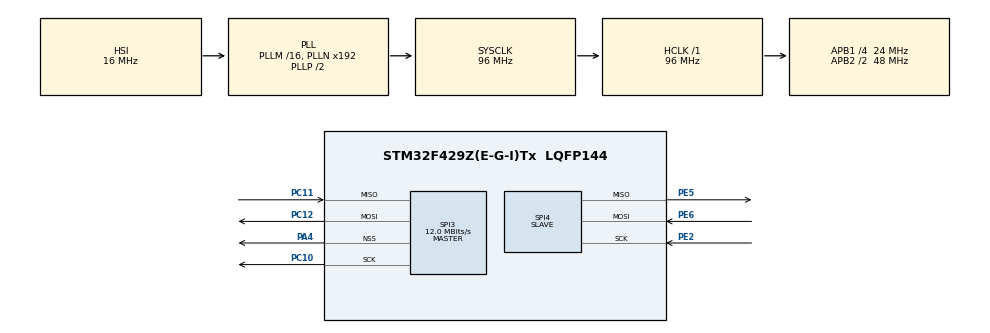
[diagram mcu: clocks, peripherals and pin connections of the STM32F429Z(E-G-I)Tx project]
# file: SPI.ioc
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Mcu.Family=STM32F4
Mcu.Name=STM32F429Z(E-G-I)Tx
Mcu.Package=LQFP144
NVIC.PriorityGroup=NVIC_PRIORITYGROUP_4
NVIC.SPI3_IRQn=true\:0\:0\:false\:false\:true
PA13.Mode=Serial_Wire
PA13.Signal=SYS_JTMS-SWDIO
PA14.Mode=Serial_Wire
PA14.Signal=SYS_JTCK-SWCLK
PA4.Mode=NSS_Signal_Hard_Output
PA4.Signal=SPI3_NSS
PC10.Mode=Full_Duplex_Master
PC10.Signal=SPI3_SCK
PC11.Mode=Full_Duplex_Master
PC11.Signal=SPI3_MISO
PC12.Mode=Full_Duplex_Master
PC12.Signal=SPI3_MOSI
PE2.Mode=Full_Duplex_Slave
PE2.Signal=SPI4_SCK
PE5.Mode=Full_Duplex_Slave
PE5.Signal=SPI4_MISO
PE6.Mode=Full_Duplex_Slave
PE6.Signal=SPI4_MOSI
PH0/OSC_IN.Mode=HSE-External-Oscillator
PH0/OSC_IN.Signal=RCC_OSC_IN
PH1/OSC_OUT.Mode=HSE-External-Oscillator
PH1/OSC_OUT.Signal=RCC_OSC_OUT
ProjectManager.HeapSize=0x200
ProjectManager.StackSize=0x400
ProjectManager.TargetToolchain=SW4STM32
RCC.AHBFreq_Value=96000000
RCC.APB1CLKDivider=RCC_HCLK_DIV4
RCC.APB1Freq_Value=24000000
RCC.APB1TimFreq_Value=48000000
RCC.APB2CLKDivider=RCC_HCLK_DIV2
RCC.APB2Freq_Value=48000000
RCC.APB2TimFreq_Value=96000000
RCC.CortexFreq_Value=96000000
RCC.HCLKFreq_Value=96000000
RCC.HSE_VALUE=8000000
RCC.HSI_VALUE=16000000
RCC.LSE_VALUE=32768
RCC.SYSCLKFreq_VALUE=96000000
RCC.SYSCLKSource=RCC_SYSCLKSOURCE_PLLCLK
RCC.VCOOutputFreq_Value=192000000
SPI3.BaudRatePrescaler=SPI_BAUDRATEPRESCALER_2
SPI3.CalculateBaudRate=12.0 MBits/s
SPI3.Direction=SPI_DIRECTION_2LINES
SPI3.Mode=SPI_MODE_MASTER
SPI3.VirtualNSS=VM_NSSHARD
SPI3.VirtualType=VM_MASTER
SPI4.Direction=SPI_DIRECTION_2LINES
SPI4.Mode=SPI_MODE_SLAVE
SPI4.VirtualType=VM_SLAVE
board=SPI

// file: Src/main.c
/**
  ******************************************************************************
  * File Name          : main.c
  * Description        : Main program body
  ******************************************************************************
  ** This notice applies to any and all portions of this file
  * that are not between comment pairs USER CODE BEGIN and
  * USER CODE END. Other portions of this file, whether
  * inserted by the user or by software development tools
  * are owned by their respective copyright owners.
  *
  * COPYRIGHT(c) 2017 STMicroelectronics
  *
  * Redistribution and use in source and binary forms, with or without modification,
  * are permitted provided that the following conditions are met:
  *   1. Redistributions of source code must retain the above copyright notice,
  *      this list of conditions and the following disclaimer.
  *   2. Redistributions in binary form must reproduce the above copyright notice,
  *      this list of conditions and the following disclaimer in the documentation
  *      and/or other materials provided with the distribution.
  *   3. Neither the name of STMicroelectronics nor the names of its contributors
  *      may be used to endorse or promote products derived from this software
  *      without specific prior written permission.
  *
  * THIS SOFTWARE IS PROVIDED BY THE COPYRIGHT HOLDERS AND CONTRIBUTORS "AS IS"
  * AND ANY EXPRESS OR IMPLIED WARRANTIES, INCLUDING, BUT NOT LIMITED TO, THE
  * IMPLIED WARRANTIES OF MERCHANTABILITY AND FITNESS FOR A PARTICULAR PURPOSE ARE
  * DISCLAIMED. IN NO EVENT SHALL THE COPYRIGHT HOLDER OR CONTRIBUTORS BE LIABLE
  * FOR ANY DIRECT, INDIRECT, INCIDENTAL, SPECIAL, EXEMPLARY, OR CONSEQUENTIAL
  * DAMAGES (INCLUDING, BUT NOT LIMITED TO, PROCUREMENT OF SUBSTITUTE GOODS OR
  * SERVICES; LOSS OF USE, DATA, OR PROFITS; OR BUSINESS INTERRUPTION) HOWEVER
  * CAUSED AND ON ANY THEORY OF LIABILITY, WHETHER IN CONTRACT, STRICT LIABILITY,
  * OR TORT (INCLUDING NEGLIGENCE OR OTHERWISE) ARISING IN ANY WAY OUT OF THE USE
  * OF THIS SOFTWARE, EVEN IF ADVISED OF THE POSSIBILITY OF SUCH DAMAGE.
  *
  ******************************************************************************
  */
#include "main.h"
#include "stm32f4xx_hal.h"

SPI_HandleTypeDef hspi3;
SPI_HandleTypeDef hspi4;

/* USER CODE BEGIN PV */
/* Private variables ---------------------------------------------------------*/

/* USER CODE END PV */

void SystemClock_Config(void);
static void MX_GPIO_Init(void);
static void MX_SPI3_Init(void);
static void MX_SPI4_Init(void);

/* USER CODE BEGIN PFP */
/* Private function prototypes -----------------------------------------------*/

/* USER CODE END PFP */

int main(void)
{

  /* USER CODE BEGIN 1 */
	char txBuffer[]={0x10,0x11,0x12,0x13};
	char rxBuffer[8];
  /* USER CODE END 1 */

  /* MCU Configuration----------------------------------------------------------*/

  /* Reset of all peripherals, Initializes the Flash interface and the Systick. */
  HAL_Init();

  /* Configure the system clock */
  SystemClock_Config();

  /* Initialize all configured peripherals */
  MX_GPIO_Init();
  MX_SPI3_Init();
  MX_SPI4_Init();

  /* Infinite loop */
  /* USER CODE BEGIN WHILE */
  while (1)
  {
	  int i;
	  volatile HAL_StatusTypeDef result;
	 	  result = HAL_SPI_TransmitReceive_IT(&hspi3,txBuffer, rxBuffer, 4);
	 	  	  if(result == HAL_ERROR){
	  	  		  while(1);
	 	  	  }
	 	 	  result = HAL_SPI_GetState(&hspi3);

	 	 	  HAL_Delay(1000);
	 	 	  for(i=0; i<4; i++){
	 	  		  rxBuffer[i] = 0;
	 	  		  txBuffer[i] += 4;
  /* USER CODE END WHILE */

  /* USER CODE BEGIN 3 */

  }
  /* USER CODE BEGIN 3 */

  }
  /* USER CODE END 3 */

}

/** System Clock Configuration
*/
void SystemClock_Config(void)
{

  RCC_OscInitTypeDef RCC_OscInitStruct;
  RCC_ClkInitTypeDef RCC_ClkInitStruct;

    /**Configure the main internal regulator output voltage
    */
  __HAL_RCC_PWR_CLK_ENABLE();

  __HAL_PWR_VOLTAGESCALING_CONFIG(PWR_REGULATOR_VOLTAGE_SCALE3);

    /**Initializes the CPU, AHB and APB busses clocks
    */
  RCC_OscInitStruct.OscillatorType = RCC_OSCILLATORTYPE_HSI;
  RCC_OscInitStruct.HSIState = RCC_HSI_ON;
  RCC_OscInitStruct.HSICalibrationValue = 16;
  RCC_OscInitStruct.PLL.PLLState = RCC_PLL_ON;
  RCC_OscInitStruct.PLL.PLLSource = RCC_PLLSOURCE_HSI;
  RCC_OscInitStruct.PLL.PLLM = 16;
  RCC_OscInitStruct.PLL.PLLN = 192;
  RCC_OscInitStruct.PLL.PLLP = RCC_PLLP_DIV2;
  RCC_OscInitStruct.PLL.PLLQ = 4;
  if (HAL_RCC_OscConfig(&RCC_OscInitStruct) != HAL_OK)
  {
    _Error_Handler(__FILE__, __LINE__);
  }

    /**Initializes the CPU, AHB and APB busses clocks
    */
  RCC_ClkInitStruct.ClockType = RCC_CLOCKTYPE_HCLK|RCC_CLOCKTYPE_SYSCLK
                              |RCC_CLOCKTYPE_PCLK1|RCC_CLOCKTYPE_PCLK2;
  RCC_ClkInitStruct.SYSCLKSource = RCC_SYSCLKSOURCE_PLLCLK;
  RCC_ClkInitStruct.AHBCLKDivider = RCC_SYSCLK_DIV1;
  RCC_ClkInitStruct.APB1CLKDivider = RCC_HCLK_DIV4;
  RCC_ClkInitStruct.APB2CLKDivider = RCC_HCLK_DIV2;

  if (HAL_RCC_ClockConfig(&RCC_ClkInitStruct, FLASH_LATENCY_3) != HAL_OK)
  {
    _Error_Handler(__FILE__, __LINE__);
  }

    /**Configure the Systick interrupt time
    */
  HAL_SYSTICK_Config(HAL_RCC_GetHCLKFreq()/1000);

    /**Configure the Systick
    */
  HAL_SYSTICK_CLKSourceConfig(SYSTICK_CLKSOURCE_HCLK);

  /* SysTick_IRQn interrupt configuration */
  HAL_NVIC_SetPriority(SysTick_IRQn, 0, 0);
}

/* SPI3 init function */
static void MX_SPI3_Init(void)
{

  hspi3.Instance = SPI3;
  hspi3.Init.Mode = SPI_MODE_MASTER;
  hspi3.Init.Direction = SPI_DIRECTION_2LINES;
  hspi3.Init.DataSize = SPI_DATASIZE_8BIT;
  hspi3.Init.CLKPolarity = SPI_POLARITY_LOW;
  hspi3.Init.CLKPhase = SPI_PHASE_1EDGE;
  hspi3.Init.NSS = SPI_NSS_HARD_OUTPUT;
  hspi3.Init.BaudRatePrescaler = SPI_BAUDRATEPRESCALER_2;
  hspi3.Init.FirstBit = SPI_FIRSTBIT_MSB;
  hspi3.Init.TIMode = SPI_TIMODE_DISABLE;
  hspi3.Init.CRCCalculation = SPI_CRCCALCULATION_DISABLE;
  hspi3.Init.CRCPolynomial = 10;
  if (HAL_SPI_Init(&hspi3) != HAL_OK)
  {
    _Error_Handler(__FILE__, __LINE__);
  }

}

/* SPI4 init function */
static void MX_SPI4_Init(void)
{

  hspi4.Instance = SPI4;
  hspi4.Init.Mode = SPI_MODE_SLAVE;
  hspi4.Init.Direction = SPI_DIRECTION_2LINES;
  hspi4.Init.DataSize = SPI_DATASIZE_8BIT;
  hspi4.Init.CLKPolarity = SPI_POLARITY_LOW;
  hspi4.Init.CLKPhase = SPI_PHASE_1EDGE;
  hspi4.Init.NSS = SPI_NSS_SOFT;
  hspi4.Init.FirstBit = SPI_FIRSTBIT_MSB;
  hspi4.Init.TIMode = SPI_TIMODE_DISABLE;
  hspi4.Init.CRCCalculation = SPI_CRCCALCULATION_DISABLE;
  hspi4.Init.CRCPolynomial = 10;
  if (HAL_SPI_Init(&hspi4) != HAL_OK)
  {
    _Error_Handler(__FILE__, __LINE__);
  }

}

/** Configure pins as
        * Analog
        * Input
        * Output
        * EVENT_OUT
        * EXTI
*/
static void MX_GPIO_Init(void)
{

  /* GPIO Ports Clock Enable */
  __HAL_RCC_GPIOE_CLK_ENABLE();
  __HAL_RCC_GPIOH_CLK_ENABLE();
  __HAL_RCC_GPIOA_CLK_ENABLE();
  __HAL_RCC_GPIOC_CLK_ENABLE();

}

void _Error_Handler(char * file, int line)
{
  while(1)
  {
  }
}

/************************ (C) COPYRIGHT STMicroelectronics *****END OF FILE****/
